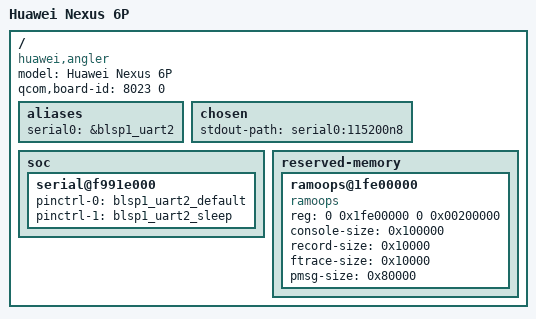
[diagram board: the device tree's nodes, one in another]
/* Copyright (c) 2015, Huawei Inc. All rights reserved.
 * Copyright (c) 2016, The Linux Foundation. All rights reserved.
 *
 * This program is free software; you can redistribute it and/or modify
 * it under the terms of the GNU General Public License version 2 and
 * only version 2 as published by the Free Software Foundation.
 *
 * This program is distributed in the hope that it will be useful,
 * but WITHOUT ANY WARRANTY; without even the implied warranty of
 * MERCHANTABILITY or FITNESS FOR A PARTICULAR PURPOSE.  See the
 * GNU General Public License for more details.
 */

/dts-v1/;

#include "msm8994.dtsi"

/ {
	model = "Huawei Nexus 6P";
	compatible = "huawei,angler", "qcom,msm8994";
	/* required for bootloader to select correct board */
	qcom,board-id = <8023 0>;

	aliases {
		serial0 = &blsp1_uart2;
	};

	chosen {
		stdout-path = "serial0:115200n8";
	};

	soc {
		serial@f991e000 {
			status = "okay";
			pinctrl-names = "default", "sleep";
			pinctrl-0 = <&blsp1_uart2_default>;
			pinctrl-1 = <&blsp1_uart2_sleep>;
		};
	};

	reserved-memory {
		#address-cells = <2>;
		#size-cells = <2>;
		ranges;

                ramoops@1fe00000 {
			compatible = "ramoops";
                        reg = <0 0x1fe00000 0 0x00200000>;
			console-size = <0x100000>;
			record-size = <0x10000>;
			ftrace-size = <0x10000>;
			pmsg-size = <0x80000>;
                };
	};
};
